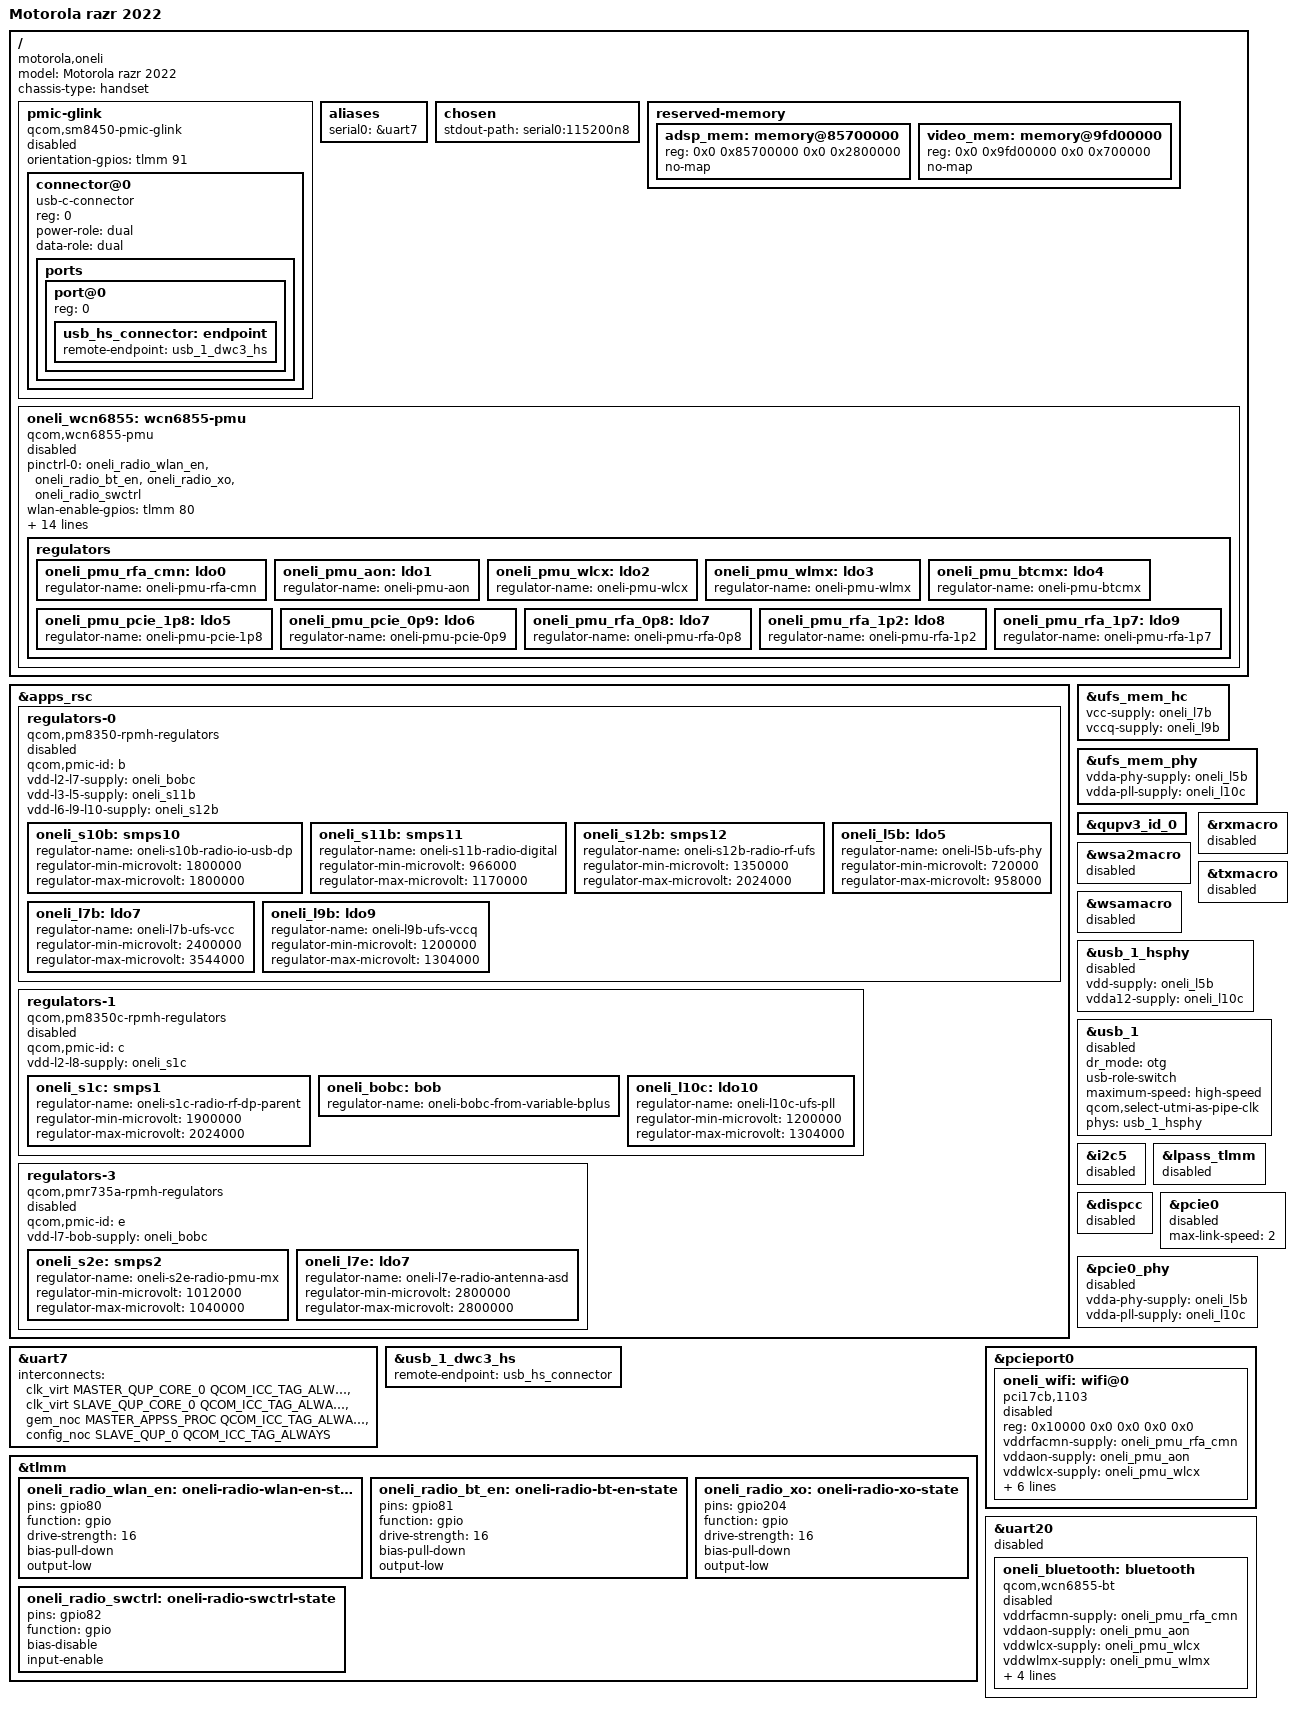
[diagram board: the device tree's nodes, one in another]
// SPDX-License-Identifier: BSD-3-Clause
/*
 * Motorola razr 2022 (oneli), minimal native Linux board description.
 *
 * Source: MotorolaMobilityLLC/kernel-devicetree
 * 90fa7be1db5bd47202673d4431408659149a7359
 * qcom/cape-moto-oneli-base.dts and qcom/cape-oneli-pvt-overlay.dts.
 *
 * [INFERRED] The upstream board compatible uses "motorola,oneli" in
 * place of Motorola's downstream "moto,oneli" property.
 */

/dts-v1/;

#include "sm8475.dtsi"
#include "pm8350.dtsi"
#include "pm8350b.dtsi"
#include "pm8350c.dtsi"
#include "pm8450.dtsi"
#include "pmk8350.dtsi"
#include "pmr735a.dtsi"

/*
 * Motorola's oneli base remaps ADSP to 0x85700000 and video to
 * 0x9fd00000. The inherited SM8450 RMTFS carveout conflicts with
 * oneli's video reservation, so do not publish it until the live
 * firmware's RMTFS address is known.
 */
/delete-node/ &adsp_mem;
/delete-node/ &video_mem;
/delete-node/ &rmtfs_mem;

/ {
	model = "Motorola razr 2022";
	compatible = "motorola,oneli", "qcom,sm8475";
	chassis-type = "handset";

	/*
	 * [INFERRED] Qualcomm PMIC GLINK Type-C source is the best upstream
	 * representation of Motorola's stock dual-role firmware interface.
	 * GPIO91 is consumed only here as an orientation input.
	 *
	 * USB2 port@0 stages the existing DWC3 endpoint pair. The SS lane
	 * PS5169 and independent DP AUX/SBU switch remain intentionally
	 * absent; the Type-C provider is not active in this bring-up tree.
	 */
	pmic-glink {
		compatible = "qcom,sm8450-pmic-glink", "qcom,pmic-glink";
		#address-cells = <1>;
		#size-cells = <0>;
		orientation-gpios = <&tlmm 91 GPIO_ACTIVE_HIGH>;
		status = "disabled";

		connector@0 {
			compatible = "usb-c-connector";
			reg = <0>;
			power-role = "dual";
			data-role = "dual";

			ports {
				#address-cells = <1>;
				#size-cells = <0>;

				port@0 {
					reg = <0>;

					usb_hs_connector: endpoint {
						remote-endpoint = <&usb_1_dwc3_hs>;
					};
				};
			};
		};
	};

	aliases {
		serial0 = &uart7;
	};

	chosen {
		stdout-path = "serial0:115200n8";
	};

	reserved-memory {
		adsp_mem: memory@85700000 {
			reg = <0x0 0x85700000 0x0 0x2800000>;
			no-map;
		};

		video_mem: memory@9fd00000 {
			reg = <0x0 0x9fd00000 0x0 0x700000>;
			no-map;
		};
	};
};

/*
 * [INFERRED] Review-only RPMh rail reconstruction for Motorola oneli.
 *
 * Rail resource names, UFS consumers, permitted voltage ranges and
 * initial voltage settings are extracted from Motorola Cape DT at
 * 90fa7be1db5bd47202673d4431408659149a7359.
 * The constraints below describe source-permitted ranges, NOT the vendor
 * boot initial settings: L5B 880000, L7B 2504000, L9B 1200000 and
 * L10C 1200000 microvolts. None are physical oneli measurements.
 * RPMh PMIC IDs and upstream node representation match the SM8450 HDK
 * comparator; some grouped parents are schematic-backed, while PMR735A
 * L7's HDK-derived parent and actual B_PLUS input remain unverified.
 *
 * Keep the provider devices disabled until the parent supply topology
 * and bootloader/firmware regulator ownership are verified. This must
 * not drive any rail in the present bring-up DT.
 */
&apps_rsc {
	regulators-0 {
		compatible = "qcom,pm8350-rpmh-regulators";
		qcom,pmic-id = "b";
		status = "disabled";

		/*
		 * B_PLUS feeds the three buck inputs physically, but is a
		 * variable battery/power-path voltage without a modelled
		 * Linux provider. Do not invent a fixed 3.7V supply.
		 * The grouped LDO inputs follow the oneli rev03 schematic.
		 */
		vdd-l2-l7-supply = <&oneli_bobc>;
		vdd-l3-l5-supply = <&oneli_s11b>;
		vdd-l6-l9-l10-supply = <&oneli_s12b>;

		oneli_s10b: smps10 {
			regulator-name = "oneli-s10b-radio-io-usb-dp";
			regulator-min-microvolt = <1800000>;
			regulator-max-microvolt = <1800000>;
		};

		oneli_s11b: smps11 {
			regulator-name = "oneli-s11b-radio-digital";
			regulator-min-microvolt = <966000>;
			regulator-max-microvolt = <1170000>;
		};

		oneli_s12b: smps12 {
			regulator-name = "oneli-s12b-radio-rf-ufs";
			regulator-min-microvolt = <1350000>;
			regulator-max-microvolt = <2024000>;
		};

		oneli_l5b: ldo5 {
			regulator-name = "oneli-l5b-ufs-phy";
			regulator-min-microvolt = <720000>;
			regulator-max-microvolt = <958000>;
		};

		oneli_l7b: ldo7 {
			regulator-name = "oneli-l7b-ufs-vcc";
			regulator-min-microvolt = <2400000>;
			regulator-max-microvolt = <3544000>;
		};

		oneli_l9b: ldo9 {
			regulator-name = "oneli-l9b-ufs-vccq";
			regulator-min-microvolt = <1200000>;
			regulator-max-microvolt = <1304000>;
		};
	};

	regulators-1 {
		compatible = "qcom,pm8350c-rpmh-regulators";
		qcom,pmic-id = "c";
		status = "disabled";

		/* Oneli source: PM8350C L2/L8 share the S1C input. */
		vdd-l2-l8-supply = <&oneli_s1c>;

		oneli_s1c: smps1 {
			regulator-name = "oneli-s1c-radio-rf-dp-parent";
			regulator-min-microvolt = <1900000>;
			regulator-max-microvolt = <2024000>;
		};

		oneli_bobc: bob {
			regulator-name = "oneli-bobc-from-variable-bplus";
			/*
			 * The physical B_PLUS input has no truthful parent
			 * regulator in Linux at this stage. No fixed supply.
			 */
		};

		oneli_l10c: ldo10 {
			regulator-name = "oneli-l10c-ufs-pll";
			regulator-min-microvolt = <1200000>;
			regulator-max-microvolt = <1304000>;
		};
	};

	/*
	 * [INFERRED] PMR735A PMIC E's L7 physical parent uses the SM8450
	 * HDK BOB input topology. The installed oneli connection is not
	 * independently traced; the entire provider stays disabled.
	 */
	regulators-3 {
		compatible = "qcom,pmr735a-rpmh-regulators";
		qcom,pmic-id = "e";
		status = "disabled";

		vdd-l7-bob-supply = <&oneli_bobc>;

		oneli_s2e: smps2 {
			regulator-name = "oneli-s2e-radio-pmu-mx";
			regulator-min-microvolt = <1012000>;
			regulator-max-microvolt = <1040000>;
		};

		oneli_l7e: ldo7 {
			regulator-name = "oneli-l7e-radio-antenna-asd";
			regulator-min-microvolt = <2800000>;
			regulator-max-microvolt = <2800000>;
		};
	};
};

/* UFS is still disabled. The supply phandles are review-only. */
&ufs_mem_hc {
	vcc-supply = <&oneli_l7b>;
	vccq-supply = <&oneli_l9b>;
};

&ufs_mem_phy {
	vdda-phy-supply = <&oneli_l5b>;
	vdda-pll-supply = <&oneli_l10c>;
};

/*
 * The GENI QUP wrapper is disabled in the inherited SM8450 tree.
 * An enabled UART child cannot probe through a disabled parent.
 */
&qupv3_id_0 {
	status = "okay";
};

/*
 * Motorola's Cape DTS selected serial@99c000 for diagnostic output.
 * UART7 belongs to QUP wrapper 0. Correct the inherited UART7
 * interconnect votes (which incorrectly refer to wrapper 2) locally.
 * Its existing GCC WRAP0_S7 clock and TLMM gpio26/27 pinctrl states
 * are consistent with Motorola's Cape pinmux definition.
 *
 * [INFERRED] The UART signals are accessible on the retail board;
 * this cannot be established without the handset.
 */
&uart7 {
	interconnects = <&clk_virt MASTER_QUP_CORE_0 QCOM_ICC_TAG_ALWAYS
				&clk_virt SLAVE_QUP_CORE_0 QCOM_ICC_TAG_ALWAYS>,
			<&gem_noc MASTER_APPSS_PROC QCOM_ICC_TAG_ALWAYS
				&config_noc SLAVE_QUP_0 QCOM_ICC_TAG_ALWAYS>;
	status = "okay";
};

/*
 * Minimal diagnostic boot does not activate LPASS audio macro endpoints.
 * The inherited SM8450 nodes are otherwise enabled while their Q6PRMCC
 * clock provider lives below a disabled ADSP remoteproc. None of these
 * audio components are needed to enumerate CPU/timer/interrupt/UART.
 *
 * Leave them disabled until the Motorola oneli audio topology/remoteproc
 * and coherent SoundWire/power clocks have an evidence-backed contract.
 */
&wsa2macro {
	status = "disabled";
};

&rxmacro {
	status = "disabled";
};

&txmacro {
	status = "disabled";
};

&wsamacro {
	status = "disabled";
};

/*
 * USB2-only diagnostic proposal, electrically INACTIVE.
 * USB owner source contract: Drzet/razr2022_nuc
 * docs/usb2_first_boot_contract_v1_2026-10-11.md
 *
 * The SM8475 eUSB2 block requires the external NXP repeater at
 * QUP0 SE5 I2C address 0x4f. That chip's exact ID, init/tuning driver
 * and PM8350C GPIO7 reset semantics are not yet resolved. Supplies
 * below come from disabled RPMh providers; do not enable any device
 * in this group until the Power/USB evidence gates are satisfied.
 */
&usb_1_hsphy {
	vdd-supply = <&oneli_l5b>;
	vdda12-supply = <&oneli_l10c>;
	status = "disabled";
};

/*
 * [INFERRED] HS-only DWC3 diagnostics: mainline UTMI pipe selection
 * avoids a dependency on QMP USB3/DP link during first USB2 debugging.
 * Source role/physical repeater path is not demonstrated.
 */
&usb_1 {
	dr_mode = "otg";
	usb-role-switch;
	maximum-speed = "high-speed";
	qcom,select-utmi-as-pipe-clk;
	phys = <&usb_1_hsphy>;
	phy-names = "usb2-phy";
	status = "disabled";
};

/* Motorola's QUP0 SE5 repeater transport; no provider bound yet. */
&i2c5 {
	status = "disabled";
};

/* Passive graph endpoint: the controller and PMIC GLINK stay disabled. */
&usb_1_dwc3_hs {
	remote-endpoint = <&usb_hs_connector>;
};

/* ADSP/LPASS is held for later audio bring-up. This inherited pinctrl
 * clock consumer cannot probe before the ADSP Q6PRMCC service is enabled.
 */
&lpass_tlmm {
	status = "disabled";
};

/*
 * DISPCC is not needed for UART-only first boot. Its inherited clock
 * parents include intentionally disabled DSI PHYs and QMP DP clocks.
 * DisplayPort and panels remain blocked on the connector/AUX contract.
 * Keep the clock controller disabled until a coherent display bring-up.
 */
&dispcc {
	status = "disabled";
};

/*
 * [INFERRED] Inherited Motorola Cape QCA6490 WLAN/BT routing, mapped to
 * upstream WCN6855 PMU/PCI/serdev bindings. The real oneli PCI/HCI
 * identities are unknown and must be learned through enumeration, NOT
 * fabricated or used as a prerequisite to disabled-source staging.
 *
 * Every new endpoint/provider remains disabled. Neither the UART20
 * QUP2 wrapper nor the PCIe0/PHY is enabled. There is one owner for
 * GPIO80 WLAN_EN, GPIO81 BT_EN and GPIO204 XO, not separate per-radio
 * GPIO consumers. SWCTRL GPIO82 has an upstream binding property but
 * the current WCN6855 sequencer does not drive it.
 *
 * PMR735A L7E is a shared WLAN antenna-switch / BT ASD 2.8V source.
 * vddasd is intentionally present to name the one shared consumer:
 * it needs the separately reviewed Wireless WCN6855 property-present
 * driver before this entire radio tree could be enabled.
 */
&tlmm {
	oneli_radio_wlan_en: oneli-radio-wlan-en-state {
		pins = "gpio80";
		function = "gpio";
		drive-strength = <16>;
		bias-pull-down;
		output-low;
	};

	oneli_radio_bt_en: oneli-radio-bt-en-state {
		pins = "gpio81";
		function = "gpio";
		drive-strength = <16>;
		bias-pull-down;
		output-low;
	};

	oneli_radio_xo: oneli-radio-xo-state {
		pins = "gpio204";
		function = "gpio";
		drive-strength = <16>;
		bias-pull-down;
		output-low;
	};

	/* GPIO82 is clock-switch state evidence, not a PMU output. */
	oneli_radio_swctrl: oneli-radio-swctrl-state {
		pins = "gpio82";
		function = "gpio";
		bias-disable;
		input-enable;
	};
};

/ {
	oneli_wcn6855: wcn6855-pmu {
		compatible = "qcom,wcn6855-pmu";
		status = "disabled";

		pinctrl-names = "default";
		pinctrl-0 = <&oneli_radio_wlan_en>, <&oneli_radio_bt_en>,
			    <&oneli_radio_xo>, <&oneli_radio_swctrl>;
		wlan-enable-gpios = <&tlmm 80 GPIO_ACTIVE_HIGH>;
		bt-enable-gpios = <&tlmm 81 GPIO_ACTIVE_HIGH>;
		/* The binding permits SWCTRL82; upstream treats it as state. */
		swctrl-gpios = <&tlmm 82 GPIO_ACTIVE_HIGH>;
		xo-clk-gpios = <&tlmm 204 GPIO_ACTIVE_HIGH>;

		vddio-supply = <&oneli_s10b>;
		vddaon-supply = <&oneli_s11b>;
		vddpmu-supply = <&oneli_s12b>;
		vddpmumx-supply = <&oneli_s2e>;
		vddpmucx-supply = <&oneli_s11b>;
		vddrfa0p95-supply = <&oneli_s11b>;
		vddrfa1p3-supply = <&oneli_s12b>;
		vddrfa1p9-supply = <&oneli_s1c>;
		vddpcie1p3-supply = <&oneli_s12b>;
		vddpcie1p9-supply = <&oneli_s1c>;
		vddasd-supply = <&oneli_l7e>;

		regulators {
			oneli_pmu_rfa_cmn: ldo0 {
				regulator-name = "oneli-pmu-rfa-cmn";
			};

			oneli_pmu_aon: ldo1 {
				regulator-name = "oneli-pmu-aon";
			};

			oneli_pmu_wlcx: ldo2 {
				regulator-name = "oneli-pmu-wlcx";
			};

			oneli_pmu_wlmx: ldo3 {
				regulator-name = "oneli-pmu-wlmx";
			};

			oneli_pmu_btcmx: ldo4 {
				regulator-name = "oneli-pmu-btcmx";
			};

			oneli_pmu_pcie_1p8: ldo5 {
				regulator-name = "oneli-pmu-pcie-1p8";
			};

			oneli_pmu_pcie_0p9: ldo6 {
				regulator-name = "oneli-pmu-pcie-0p9";
			};

			oneli_pmu_rfa_0p8: ldo7 {
				regulator-name = "oneli-pmu-rfa-0p8";
			};

			oneli_pmu_rfa_1p2: ldo8 {
				regulator-name = "oneli-pmu-rfa-1p2";
			};

			oneli_pmu_rfa_1p7: ldo9 {
				regulator-name = "oneli-pmu-rfa-1p7";
			};
		};
	};
};

/* The upstream SoC already owns PCIe0 PERST94, CLKREQ95, WAKE96. */
&pcie0 {
	max-link-speed = <2>;
	status = "disabled";
};

/*
 * Motorola RC0's two PHY regulator votes are PM8350 L5B (~0.88V)
 * and PM8350C L10C (~1.2V); unlike the HDK's L6B comparator.
 */
&pcie0_phy {
	vdda-phy-supply = <&oneli_l5b>;
	vdda-pll-supply = <&oneli_l10c>;
	status = "disabled";
};

&pcieport0 {
	oneli_wifi: wifi@0 {
		/* Expected generic match, not a measured oneli endpoint ID. */
		compatible = "pci17cb,1103";
		reg = <0x10000 0x0 0x0 0x0 0x0>;
		status = "disabled";

		vddrfacmn-supply = <&oneli_pmu_rfa_cmn>;
		vddaon-supply = <&oneli_pmu_aon>;
		vddwlcx-supply = <&oneli_pmu_wlcx>;
		vddwlmx-supply = <&oneli_pmu_wlmx>;
		vddpcie1p8-supply = <&oneli_pmu_pcie_1p8>;
		vddpcie0p9-supply = <&oneli_pmu_pcie_0p9>;
		vddrfa0p8-supply = <&oneli_pmu_rfa_0p8>;
		vddrfa1p2-supply = <&oneli_pmu_rfa_1p2>;
		vddrfa1p8-supply = <&oneli_pmu_rfa_1p7>;
	};
};

/*
 * QUP2 wrapper remains disabled; UART20 uses the inherited
 * qup_uart20_default TLMM76/77/78/79 hardware mux and GENI S5.
 * UART7 / serial0 remains the only enabled diagnostic serial.
 */
&uart20 {
	status = "disabled";

	oneli_bluetooth: bluetooth {
		compatible = "qcom,wcn6855-bt";
		status = "disabled";

		vddrfacmn-supply = <&oneli_pmu_rfa_cmn>;
		vddaon-supply = <&oneli_pmu_aon>;
		vddwlcx-supply = <&oneli_pmu_wlcx>;
		vddwlmx-supply = <&oneli_pmu_wlmx>;
		vddbtcmx-supply = <&oneli_pmu_btcmx>;
		vddrfa0p8-supply = <&oneli_pmu_rfa_0p8>;
		vddrfa1p2-supply = <&oneli_pmu_rfa_1p2>;
		vddrfa1p7-supply = <&oneli_pmu_rfa_1p7>;
	};
};
